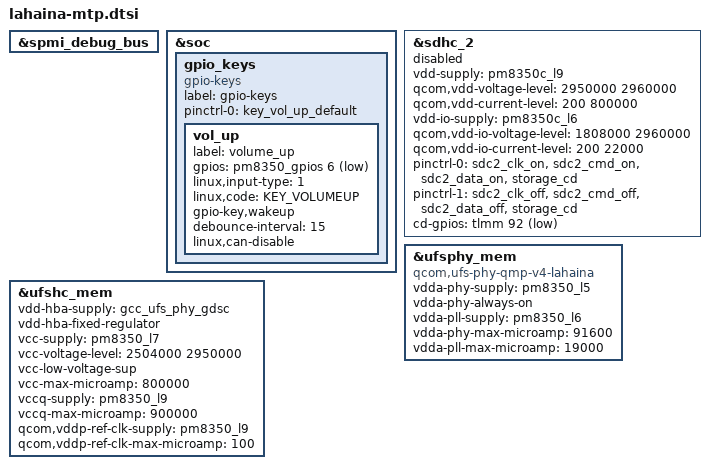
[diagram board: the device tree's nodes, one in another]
#include <dt-bindings/gpio/gpio.h>
#include <dt-bindings/input/input.h>

#include "lahaina-pmic-overlay.dtsi"
#include "lahaina-audio-overlay.dtsi"

&spmi_debug_bus {
	status = "ok";
};

&soc {
	gpio_keys {
		compatible = "gpio-keys";
		label = "gpio-keys";

		pinctrl-names = "default";
		pinctrl-0 = <&key_vol_up_default>;

		vol_up {
			label = "volume_up";
			gpios = <&pm8350_gpios 6 GPIO_ACTIVE_LOW>;
			linux,input-type = <1>;
			linux,code = <KEY_VOLUMEUP>;
			gpio-key,wakeup;
			debounce-interval = <15>;
			linux,can-disable;
		};
	};
};

&sdhc_2 {
	vdd-supply = <&pm8350c_l9>;
	qcom,vdd-voltage-level = <2950000 2960000>;
	qcom,vdd-current-level = <200 800000>;

	vdd-io-supply = <&pm8350c_l6>;
	qcom,vdd-io-voltage-level = <1808000 2960000>;
	qcom,vdd-io-current-level = <200 22000>;

	pinctrl-names = "active", "sleep";
	pinctrl-0 = <&sdc2_clk_on  &sdc2_cmd_on &sdc2_data_on &storage_cd>;
	pinctrl-1 = <&sdc2_clk_off &sdc2_cmd_off &sdc2_data_off &storage_cd>;

	cd-gpios = <&tlmm 92 GPIO_ACTIVE_LOW>;

	status = "disabled";
};


&ufsphy_mem {
	compatible = "qcom,ufs-phy-qmp-v4-lahaina";

	vdda-phy-supply = <&pm8350_l5>;
	vdda-phy-always-on;
	vdda-pll-supply = <&pm8350_l6>;
	vdda-phy-max-microamp = <91600>;
	vdda-pll-max-microamp = <19000>;

	status = "ok";
};

&ufshc_mem {
	vdd-hba-supply = <&gcc_ufs_phy_gdsc>;
	vdd-hba-fixed-regulator;

	vcc-supply = <&pm8350_l7>;
	vcc-voltage-level = <2504000 2950000>;
	vcc-low-voltage-sup;
	vcc-max-microamp = <800000>;

	vccq-supply = <&pm8350_l9>;
	vccq-max-microamp = <900000>;

	qcom,vddp-ref-clk-supply = <&pm8350_l9>;
	qcom,vddp-ref-clk-max-microamp = <100>;

	status = "ok";
};

